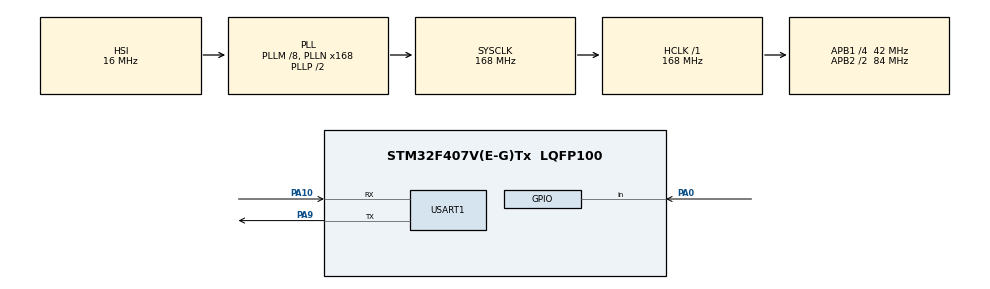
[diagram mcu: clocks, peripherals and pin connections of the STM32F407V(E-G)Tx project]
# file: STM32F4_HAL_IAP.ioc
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Mcu.Family=STM32F4
Mcu.Name=STM32F407V(E-G)Tx
Mcu.Package=LQFP100
NVIC.PriorityGroup=NVIC_PRIORITYGROUP_4
PA0-WKUP.Signal=GPIO_Input
PA10.Mode=Asynchronous
PA10.Signal=USART1_RX
PA9.Mode=Asynchronous
PA9.Signal=USART1_TX
ProjectManager.HeapSize=0x200
ProjectManager.StackSize=0x400
ProjectManager.TargetToolchain=STM32CubeIDE
RCC.48MHZClocksFreq_Value=84000000
RCC.AHBFreq_Value=168000000
RCC.APB1CLKDivider=RCC_HCLK_DIV4
RCC.APB1Freq_Value=42000000
RCC.APB1TimFreq_Value=84000000
RCC.APB2CLKDivider=RCC_HCLK_DIV2
RCC.APB2Freq_Value=84000000
RCC.APB2TimFreq_Value=168000000
RCC.CortexFreq_Value=168000000
RCC.HCLKFreq_Value=168000000
RCC.HSE_VALUE=25000000
RCC.HSI_VALUE=16000000
RCC.LSE_VALUE=32768
RCC.PLLM=8
RCC.PLLN=168
RCC.SYSCLKFreq_VALUE=168000000
RCC.SYSCLKSource=RCC_SYSCLKSOURCE_PLLCLK
RCC.VCOOutputFreq_Value=336000000
USART1.VirtualMode=VM_ASYNC
board=custom

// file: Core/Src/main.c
/* USER CODE BEGIN Header */
/**
  ******************************************************************************
  * @file           : main.c
  * @brief          : Main program body
  ******************************************************************************
  * @attention
  *
  * <h2><center>&copy; Copyright (c) 2020 STMicroelectronics.
  * All rights reserved.</center></h2>
  *
  * This software component is licensed by ST under BSD 3-Clause license,
  * the "License"; You may not use this file except in compliance with the
  * License. You may obtain a copy of the License at:
  *                        opensource.org/licenses/BSD-3-Clause
  *
  ******************************************************************************
  */
/* USER CODE END Header */

#include "main.h"

/* USER CODE BEGIN Includes */
#include "menu.h"
/* USER CODE END Includes */

UART_HandleTypeDef huart1;

/* USER CODE BEGIN PV */
extern pFunction JumpToApplication;
extern uint32_t JumpAddress;
/* USER CODE END PV */

void SystemClock_Config(void);
static void MX_GPIO_Init(void);
static void MX_USART1_UART_Init(void);

int main(void)
{

  /* MCU Configuration--------------------------------------------------------*/

  /* Reset of all peripherals, Initializes the Flash interface and the Systick. */
  HAL_Init();

  /* Configure the system clock */
  SystemClock_Config();

  /* Initialize all configured peripherals */
  MX_GPIO_Init();
  //MX_USART1_UART_Init();
  /* USER CODE BEGIN 2 */
  int a = ((*(__IO uint32_t*)APPLICATION_ADDRESS) & 0x2FFE0000 );

  if(HAL_GPIO_ReadPin(GPIOA,GPIO_PIN_0) != GPIO_PIN_RESET)
  {
	  MX_USART1_UART_Init();
	  Main_Menu();
  }
  else
  {

	    /* Test if user code is programmed starting from address "APPLICATION_ADDRESS" */
	  if ( a == 0x20000000)
	 {
	   /* Jump to user application */
	   JumpAddress = *(__IO uint32_t*) (APPLICATION_ADDRESS + 4);
	   JumpToApplication = (pFunction) JumpAddress;
	   /* Initialize user application's Stack Pointer */
	   __set_MSP(*(__IO uint32_t*) APPLICATION_ADDRESS);
	   JumpToApplication();
	 }
  }
  /* USER CODE END 2 */

  /* Infinite loop */
  while (1)
  {

  }
}

void SystemClock_Config(void)
{
  RCC_OscInitTypeDef RCC_OscInitStruct = {0};
  RCC_ClkInitTypeDef RCC_ClkInitStruct = {0};

  /** Configure the main internal regulator output voltage
  */
  __HAL_RCC_PWR_CLK_ENABLE();
  __HAL_PWR_VOLTAGESCALING_CONFIG(PWR_REGULATOR_VOLTAGE_SCALE1);
  /** Initializes the CPU, AHB and APB busses clocks
  */
  RCC_OscInitStruct.OscillatorType = RCC_OSCILLATORTYPE_HSI;
  RCC_OscInitStruct.HSIState = RCC_HSI_ON;
  RCC_OscInitStruct.HSICalibrationValue = RCC_HSICALIBRATION_DEFAULT;
  RCC_OscInitStruct.PLL.PLLState = RCC_PLL_ON;
  RCC_OscInitStruct.PLL.PLLSource = RCC_PLLSOURCE_HSI;
  RCC_OscInitStruct.PLL.PLLM = 8;
  RCC_OscInitStruct.PLL.PLLN = 168;
  RCC_OscInitStruct.PLL.PLLP = RCC_PLLP_DIV2;
  RCC_OscInitStruct.PLL.PLLQ = 4;
  if (HAL_RCC_OscConfig(&RCC_OscInitStruct) != HAL_OK)
  {
    Error_Handler();
  }
  /** Initializes the CPU, AHB and APB busses clocks
  */
  RCC_ClkInitStruct.ClockType = RCC_CLOCKTYPE_HCLK|RCC_CLOCKTYPE_SYSCLK
                              |RCC_CLOCKTYPE_PCLK1|RCC_CLOCKTYPE_PCLK2;
  RCC_ClkInitStruct.SYSCLKSource = RCC_SYSCLKSOURCE_PLLCLK;
  RCC_ClkInitStruct.AHBCLKDivider = RCC_SYSCLK_DIV1;
  RCC_ClkInitStruct.APB1CLKDivider = RCC_HCLK_DIV4;
  RCC_ClkInitStruct.APB2CLKDivider = RCC_HCLK_DIV2;

  if (HAL_RCC_ClockConfig(&RCC_ClkInitStruct, FLASH_LATENCY_5) != HAL_OK)
  {
    Error_Handler();
  }
}

static void MX_USART1_UART_Init(void)
{

  huart1.Instance = USART1;
  huart1.Init.BaudRate = 115200;
  huart1.Init.WordLength = UART_WORDLENGTH_8B;
  huart1.Init.StopBits = UART_STOPBITS_1;
  huart1.Init.Parity = UART_PARITY_NONE;
  huart1.Init.Mode = UART_MODE_TX_RX;
  huart1.Init.HwFlowCtl = UART_HWCONTROL_NONE;
  huart1.Init.OverSampling = UART_OVERSAMPLING_16;
  if (HAL_UART_Init(&huart1) != HAL_OK)
  {
    Error_Handler();
  }

}

static void MX_GPIO_Init(void)
{
  GPIO_InitTypeDef GPIO_InitStruct = {0};

  /* GPIO Ports Clock Enable */
  __HAL_RCC_GPIOA_CLK_ENABLE();

  /*Configure GPIO pin : PA0 */
  GPIO_InitStruct.Pin = GPIO_PIN_0;
  GPIO_InitStruct.Mode = GPIO_MODE_INPUT;
  GPIO_InitStruct.Pull = GPIO_NOPULL;
  HAL_GPIO_Init(GPIOA, &GPIO_InitStruct);

}

void Error_Handler(void)
{
}

/************************ (C) COPYRIGHT STMicroelectronics *****END OF FILE****/
